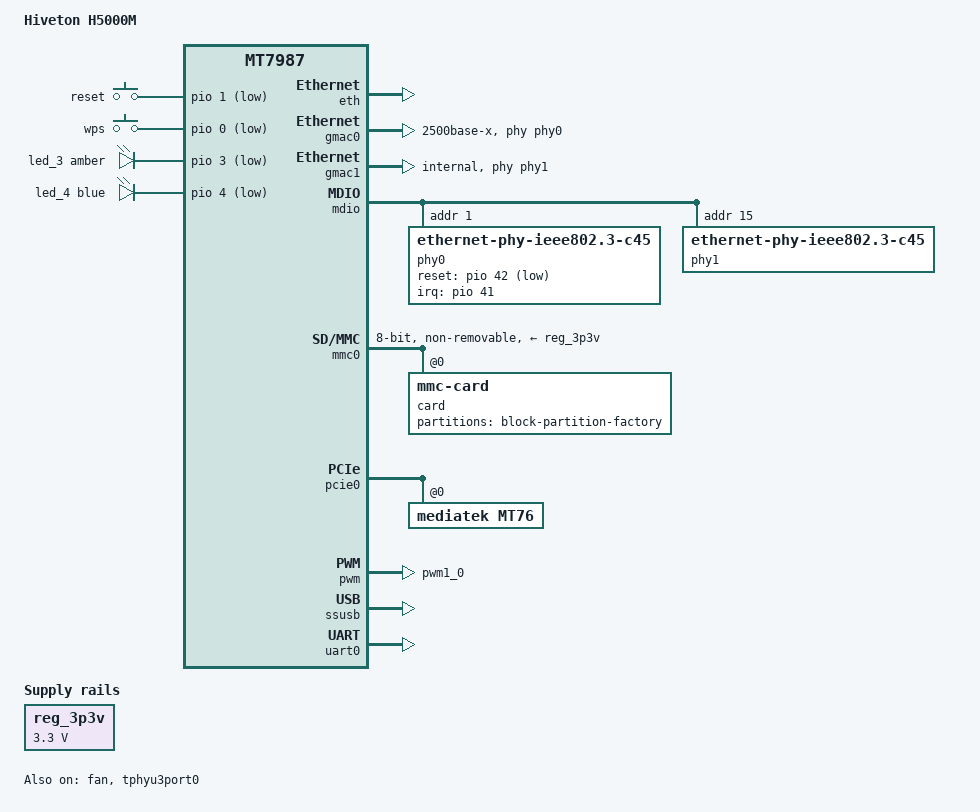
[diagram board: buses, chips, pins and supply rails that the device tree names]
// SPDX-License-Identifier: (GPL-2.0 OR MIT)

/dts-v1/;
#include "mt7987a.dtsi"
#include <dt-bindings/input/input.h>

/ {
	model = "Hiveton H5000M";
	compatible = "hiveton,h5000m", "mediatek,mt7987";

	chosen {
		bootargs = "console=ttyS0,115200n1 \
			    earlycon=uart8250,mmio32,0x11000000 \
			    root=PARTLABEL=rootfs rootwait";
	};

	gpio-keys {
		compatible = "gpio-keys";

		reset {
			label = "reset";
			linux,code = <KEY_RESTART>;
			gpios = <&pio 1 GPIO_ACTIVE_LOW>;
			debounce-interval = <10>;
		};

		wps {
			label = "wps";
			linux,code = <KEY_WPS_BUTTON>;
			gpios = <&pio 0 GPIO_ACTIVE_LOW>;
			debounce-interval = <10>;
		};
	};

	/*
	* LED Indicator Layout
	* -------------------
	* Total of 5 LED indicators, viewed from front with antenna facing up (left to right):
	* 
	* LED 1: 5G Module indicator
	* LED 2: Built-in 2.5G Ethernet port indicator
	* LED 3: User-definable (configurable in system)
	* LED 4: User-definable (configurable in system)
	* LED 5: Power indicator
	* 
	* Note: 
	* - LEDs 1, 2, and 5 are hardware-controlled and cannot be modified via software
	* - In vendor firmware, LEDs 3 and 4 are used as WiFi link activity indicators 
	*   for dual-band (2.4GHz/5GHz) respectively
	*/
	leds {
		compatible = "gpio-leds";

		led_3: led-3 {
			function = LED_FUNCTION_WLAN_2GHZ;
			color = <LED_COLOR_ID_AMBER>;
			gpios = <&pio 3 GPIO_ACTIVE_LOW>;
		};

		led_4: led-4 {
			function = LED_FUNCTION_WLAN_5GHZ;
			color = <LED_COLOR_ID_BLUE>;
			gpios = <&pio 4 GPIO_ACTIVE_LOW>;
		};
	};

	reg_3p3v: regulator-3p3v {
		compatible = "regulator-fixed";
		regulator-name = "fixed-3.3V";
		regulator-min-microvolt = <3300000>;
		regulator-max-microvolt = <3300000>;
		regulator-boot-on;
		regulator-always-on;
	};
};

&eth {
	status = "okay";
};

&fan {
	pwms = <&pwm 1 50000 0>;
	status = "okay";
};

&gmac0 {
	phy-mode = "2500base-x";
	phy-handle = <&phy0>;
	status = "okay";
};

&gmac1 {
	phy-mode = "internal";
	phy-handle = <&phy1>;
	status = "okay";
};

&mdio {
	/* RTL8221B-VB-CG 2.5Gbps PHY (away from power) eth0 */
	phy0: phy@1 {
		compatible = "ethernet-phy-ieee802.3-c45";
		reg = <1>;
		reset-gpios = <&pio 42 GPIO_ACTIVE_LOW>;
		reset-assert-us = <100000>;
		reset-deassert-us = <100000>;
		interrupt-parent = <&pio>;
		interrupts = <41 IRQ_TYPE_LEVEL_LOW>;
		realtek,aldps-enable;
	};

	/* built-in 2.5G Ethernet PHY (near power) eth1 */
	phy1: phy@15 {
		compatible = "ethernet-phy-ieee802.3-c45";
		reg = <15>;
		pinctrl-names = "i2p5gbe-led";
		pinctrl-0 = <&i2p5gbe_led0_pins>;
	};
};

&mmc0 {
	pinctrl-names = "default", "state_uhs";
	pinctrl-0 = <&mmc_pins_default>;
	pinctrl-1 = <&mmc_pins_uhs>;
	bus-width = <8>;
	max-frequency = <48000000>;
	cap-mmc-highspeed;
	vmmc-supply = <&reg_3p3v>;
	non-removable;
	status = "okay";
	
	card@0 {
		compatible = "mmc-card";
		reg = <0>;

		block {
			compatible = "block-device";

			partitions {
				block-partition-factory {
					partname = "factory";

					nvmem-layout {
						compatible = "fixed-layout";
						#address-cells = <1>;
						#size-cells = <1>;

						eeprom_factory_0: eeprom@0 {
							reg = <0x0 0x1e00>;
						};
					};
				};
			};
		};
	};
};

&pcie0 {
	pinctrl-names = "default";
	pinctrl-0 = <&pcie0_pins>;
	status = "okay";
	
	pcie@0,0 {
		reg = <0x0000 0 0 0 0>;
		#address-cells = <3>;
		#size-cells = <2>;

		mt76@0,0 {
			compatible = "mediatek,mt76";
			reg = <0x0000 0 0 0 0>;

			nvmem-cells = <&eeprom_factory_0>;
			nvmem-cell-names = "eeprom";
		};
	};
};

&pio {
	pwm_fan_pins: pwm-fan-pins {
		mux {
			function = "pwm";
			groups = "pwm1_0";
		};
	};
};

&pwm {
	status = "okay";
	pinctrl-names = "default";
	pinctrl-0 = <&pwm_fan_pins>;
};

&ssusb {
	status = "okay";
	vusb33-supply = <&reg_3p3v>;
};

&tphyu3port0 {
	status = "okay";
};

&uart0 {
	pinctrl-names = "default";
	pinctrl-0 = <&uart0_pins>;
	status = "okay";
};
